# ECC_AGGR10_ECC_AGGR register map
Vendor: Texas Instruments
Peripheral module from a debugger description file (folder J721S2).
Registers are 32-bit, access not given, reset 0x0 unless marked. A register's access mark holds for its fields unless they carry their own. Offsets are as the file gives them; lines under a group give offsets from that group; [hi:lo] are bit positions; {n}, {i} and the like mark numbered series; 'fields as' and 'values as' point back to an identical list; <NAME> marks a mode.

## ECC_AGGR10_ECC_AGGR
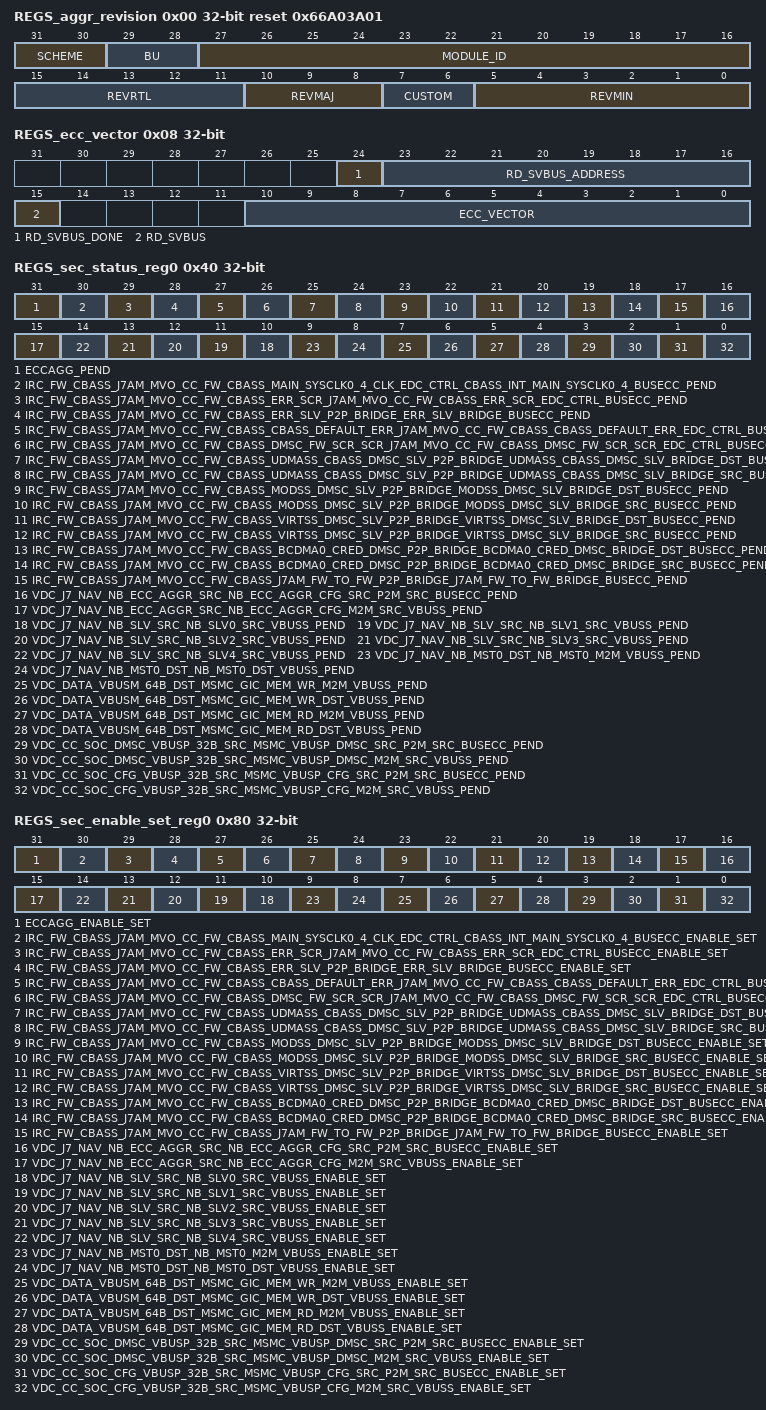
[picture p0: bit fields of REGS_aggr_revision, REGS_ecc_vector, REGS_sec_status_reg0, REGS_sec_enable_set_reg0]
0x00 REGS_aggr_revision ro reset 0x66A03A01 — Revision parameters
  [31:30] SCHEME
  [29:28] BU
  [27:16] MODULE_ID
  [15:11] REVRTL — RTL version
  [10:8] REVMAJ — Major version
  [7:6] CUSTOM — Custom version
  [5:0] REVMIN — Minor version
0x08 REGS_ecc_vector — ECC Vector Register
  [24] RD_SVBUS_DONE — Status to indicate if read on serial VBUS is complete, write of any value will clear this bit. (access R/W1TC)
  [23:16] RD_SVBUS_ADDRESS rw — Read address
  [15] RD_SVBUS — Write 1 to trigger a read on the serial VBUS (access R/W1TS)
  [10:0] ECC_VECTOR rw — Value written to select the corresponding ECC RAM for control or status
0x0C REGS_misc_status ro reset 0x20 — Misc Status
  [10:0] NUM_RAMS — Indicates the number of RAMS serviced by the ECC aggregator
0x10 REGS_reserved_svbus rw — Reference other documents that contain the ECC RAM wrapper and EDC controller serial vbus register sets.
  [31:0] DATA — Serial VBUS register data
0x3C REGS_sec_eoi_reg — EOI Register
  [0] EOI_WR — EOI Register (access R/W1TS)
0x40 REGS_sec_status_reg0 — Interrupt Status Register 0
  [31] ECCAGG_PEND — Interrupt Pending Status for eccagg_pend (access R/W1TS)
  [30] IRC_FW_CBASS_J7AM_MVO_CC_FW_CBASS_MAIN_SYSCLK0_4_CLK_EDC_CTRL_CBASS_INT_MAIN_SYSCLK0_4_BUSECC_PEND — Interrupt Pending Status for Irc_fw_cbass_j7am_mvo_cc_fw_cbass_main_SYSCLK0_4_clk_edc_ctrl_cbass_int_main_SYSCLK0_4_busecc_pend (access R/W1TS)
  [29] IRC_FW_CBASS_J7AM_MVO_CC_FW_CBASS_ERR_SCR_J7AM_MVO_CC_FW_CBASS_ERR_SCR_EDC_CTRL_BUSECC_PEND — Interrupt Pending Status for Irc_fw_cbass_j7am_mvo_cc_fw_cbass_err_scr_j7am_mvo_cc_fw_cbass_err_scr_edc_ctrl_busecc_pend (access R/W1TS)
  [28] IRC_FW_CBASS_J7AM_MVO_CC_FW_CBASS_ERR_SLV_P2P_BRIDGE_ERR_SLV_BRIDGE_BUSECC_PEND — Interrupt Pending Status for Irc_fw_cbass_j7am_mvo_cc_fw_cbass_err_slv_p2p_bridge_err_slv_bridge_busecc_pend (access R/W1TS)
  [27] IRC_FW_CBASS_J7AM_MVO_CC_FW_CBASS_CBASS_DEFAULT_ERR_J7AM_MVO_CC_FW_CBASS_CBASS_DEFAULT_ERR_EDC_CTRL_BUSECC_PEND — Interrupt Pending Status for Irc_fw_cbass_j7am_mvo_cc_fw_cbass_cbass_default_err_j7am_mvo_cc_fw_cbass_cbass_default_err_edc_ctrl_busecc_pend (access R/W1TS)
  [26] IRC_FW_CBASS_J7AM_MVO_CC_FW_CBASS_DMSC_FW_SCR_SCR_J7AM_MVO_CC_FW_CBASS_DMSC_FW_SCR_SCR_EDC_CTRL_BUSECC_PEND — Interrupt Pending Status for Irc_fw_cbass_j7am_mvo_cc_fw_cbass_dmsc_fw_scr_scr_j7am_mvo_cc_fw_cbass_dmsc_fw_scr_scr_edc_ctrl_busecc_pend (access R/W1TS)
  [25] IRC_FW_CBASS_J7AM_MVO_CC_FW_CBASS_UDMASS_CBASS_DMSC_SLV_P2P_BRIDGE_UDMASS_CBASS_DMSC_SLV_BRIDGE_DST_BUSECC_PEND — Interrupt Pending Status for Irc_fw_cbass_j7am_mvo_cc_fw_cbass_udmass_cbass_dmsc_slv_p2p_bridge_udmass_cbass_dmsc_slv_bridge_dst_busecc_pend (access R/W1TS)
  [24] IRC_FW_CBASS_J7AM_MVO_CC_FW_CBASS_UDMASS_CBASS_DMSC_SLV_P2P_BRIDGE_UDMASS_CBASS_DMSC_SLV_BRIDGE_SRC_BUSECC_PEND — Interrupt Pending Status for Irc_fw_cbass_j7am_mvo_cc_fw_cbass_udmass_cbass_dmsc_slv_p2p_bridge_udmass_cbass_dmsc_slv_bridge_src_busecc_pend (access R/W1TS)
  [23] IRC_FW_CBASS_J7AM_MVO_CC_FW_CBASS_MODSS_DMSC_SLV_P2P_BRIDGE_MODSS_DMSC_SLV_BRIDGE_DST_BUSECC_PEND — Interrupt Pending Status for Irc_fw_cbass_j7am_mvo_cc_fw_cbass_modss_dmsc_slv_p2p_bridge_modss_dmsc_slv_bridge_dst_busecc_pend (access R/W1TS)
  [22] IRC_FW_CBASS_J7AM_MVO_CC_FW_CBASS_MODSS_DMSC_SLV_P2P_BRIDGE_MODSS_DMSC_SLV_BRIDGE_SRC_BUSECC_PEND — Interrupt Pending Status for Irc_fw_cbass_j7am_mvo_cc_fw_cbass_modss_dmsc_slv_p2p_bridge_modss_dmsc_slv_bridge_src_busecc_pend (access R/W1TS)
  [21] IRC_FW_CBASS_J7AM_MVO_CC_FW_CBASS_VIRTSS_DMSC_SLV_P2P_BRIDGE_VIRTSS_DMSC_SLV_BRIDGE_DST_BUSECC_PEND — Interrupt Pending Status for Irc_fw_cbass_j7am_mvo_cc_fw_cbass_virtss_dmsc_slv_p2p_bridge_virtss_dmsc_slv_bridge_dst_busecc_pend (access R/W1TS)
  [20] IRC_FW_CBASS_J7AM_MVO_CC_FW_CBASS_VIRTSS_DMSC_SLV_P2P_BRIDGE_VIRTSS_DMSC_SLV_BRIDGE_SRC_BUSECC_PEND — Interrupt Pending Status for Irc_fw_cbass_j7am_mvo_cc_fw_cbass_virtss_dmsc_slv_p2p_bridge_virtss_dmsc_slv_bridge_src_busecc_pend (access R/W1TS)
  [19] IRC_FW_CBASS_J7AM_MVO_CC_FW_CBASS_BCDMA0_CRED_DMSC_P2P_BRIDGE_BCDMA0_CRED_DMSC_BRIDGE_DST_BUSECC_PEND — Interrupt Pending Status for Irc_fw_cbass_j7am_mvo_cc_fw_cbass_bcdma0_cred_dmsc_p2p_bridge_bcdma0_cred_dmsc_bridge_dst_busecc_pend (access R/W1TS)
  [18] IRC_FW_CBASS_J7AM_MVO_CC_FW_CBASS_BCDMA0_CRED_DMSC_P2P_BRIDGE_BCDMA0_CRED_DMSC_BRIDGE_SRC_BUSECC_PEND — Interrupt Pending Status for Irc_fw_cbass_j7am_mvo_cc_fw_cbass_bcdma0_cred_dmsc_p2p_bridge_bcdma0_cred_dmsc_bridge_src_busecc_pend (access R/W1TS)
  [17] IRC_FW_CBASS_J7AM_MVO_CC_FW_CBASS_J7AM_FW_TO_FW_P2P_BRIDGE_J7AM_FW_TO_FW_BRIDGE_BUSECC_PEND — Interrupt Pending Status for Irc_fw_cbass_j7am_mvo_cc_fw_cbass_j7am_fw_to_fw_p2p_bridge_j7am_fw_to_fw_bridge_busecc_pend (access R/W1TS)
  [16] VDC_J7_NAV_NB_ECC_AGGR_SRC_NB_ECC_AGGR_CFG_SRC_P2M_SRC_BUSECC_PEND — Interrupt Pending Status for vdc_j7_nav_nb_ecc_aggr_src_nb_ecc_aggr_cfg_src_p2m_src_busecc_pend (access R/W1TS)
  [15] VDC_J7_NAV_NB_ECC_AGGR_SRC_NB_ECC_AGGR_CFG_M2M_SRC_VBUSS_PEND — Interrupt Pending Status for vdc_j7_nav_nb_ecc_aggr_src_nb_ecc_aggr_cfg_m2m_src_vbuss_pend (access R/W1TS)
  [n+10] VDC_J7_NAV_NB_SLV_SRC_NB_SLV{n}_SRC_VBUSS_PEND (n=0..4) — Interrupt Pending Status for vdc_j7_nav_nb_slv_src_nb_slv{n}_src_vbuss_pend (access R/W1TS)
  [9] VDC_J7_NAV_NB_MST0_DST_NB_MST0_M2M_VBUSS_PEND — Interrupt Pending Status for vdc_j7_nav_nb_mst0_dst_nb_mst0_m2m_vbuss_pend (access R/W1TS)
  [8] VDC_J7_NAV_NB_MST0_DST_NB_MST0_DST_VBUSS_PEND — Interrupt Pending Status for vdc_j7_nav_nb_mst0_dst_nb_mst0_dst_vbuss_pend (access R/W1TS)
  [7] VDC_DATA_VBUSM_64B_DST_MSMC_GIC_MEM_WR_M2M_VBUSS_PEND — Interrupt Pending Status for vdc_data_vbusm_64b_dst_msmc_gic_mem_wr_m2m_vbuss_pend (access R/W1TS)
  [6] VDC_DATA_VBUSM_64B_DST_MSMC_GIC_MEM_WR_DST_VBUSS_PEND — Interrupt Pending Status for vdc_data_vbusm_64b_dst_msmc_gic_mem_wr_dst_vbuss_pend (access R/W1TS)
  [5] VDC_DATA_VBUSM_64B_DST_MSMC_GIC_MEM_RD_M2M_VBUSS_PEND — Interrupt Pending Status for vdc_data_vbusm_64b_dst_msmc_gic_mem_rd_m2m_vbuss_pend (access R/W1TS)
  [4] VDC_DATA_VBUSM_64B_DST_MSMC_GIC_MEM_RD_DST_VBUSS_PEND — Interrupt Pending Status for vdc_data_vbusm_64b_dst_msmc_gic_mem_rd_dst_vbuss_pend (access R/W1TS)
  [3] VDC_CC_SOC_DMSC_VBUSP_32B_SRC_MSMC_VBUSP_DMSC_SRC_P2M_SRC_BUSECC_PEND — Interrupt Pending Status for vdc_cc_soc_dmsc_vbusp_32b_src_msmc_vbusp_dmsc_src_p2m_src_busecc_pend (access R/W1TS)
  [2] VDC_CC_SOC_DMSC_VBUSP_32B_SRC_MSMC_VBUSP_DMSC_M2M_SRC_VBUSS_PEND — Interrupt Pending Status for vdc_cc_soc_dmsc_vbusp_32b_src_msmc_vbusp_dmsc_m2m_src_vbuss_pend (access R/W1TS)
  [1] VDC_CC_SOC_CFG_VBUSP_32B_SRC_MSMC_VBUSP_CFG_SRC_P2M_SRC_BUSECC_PEND — Interrupt Pending Status for vdc_cc_soc_cfg_vbusp_32b_src_msmc_vbusp_cfg_src_p2m_src_busecc_pend (access R/W1TS)
  [0] VDC_CC_SOC_CFG_VBUSP_32B_SRC_MSMC_VBUSP_CFG_M2M_SRC_VBUSS_PEND — Interrupt Pending Status for vdc_cc_soc_cfg_vbusp_32b_src_msmc_vbusp_cfg_m2m_src_vbuss_pend (access R/W1TS)
0x80 REGS_sec_enable_set_reg0 — Interrupt Enable Set Register 0
  [31] ECCAGG_ENABLE_SET — Interrupt Enable Set Register for eccagg_pend (access R/W1TS)
  [30] IRC_FW_CBASS_J7AM_MVO_CC_FW_CBASS_MAIN_SYSCLK0_4_CLK_EDC_CTRL_CBASS_INT_MAIN_SYSCLK0_4_BUSECC_ENABLE_SET — Interrupt Enable Set Register for Irc_fw_cbass_j7am_mvo_cc_fw_cbass_main_SYSCLK0_4_clk_edc_ctrl_cbass_int_main_SYSCLK0_4_busecc_pend (access R/W1TS)
  [29] IRC_FW_CBASS_J7AM_MVO_CC_FW_CBASS_ERR_SCR_J7AM_MVO_CC_FW_CBASS_ERR_SCR_EDC_CTRL_BUSECC_ENABLE_SET — Interrupt Enable Set Register for Irc_fw_cbass_j7am_mvo_cc_fw_cbass_err_scr_j7am_mvo_cc_fw_cbass_err_scr_edc_ctrl_busecc_pend (access R/W1TS)
  [28] IRC_FW_CBASS_J7AM_MVO_CC_FW_CBASS_ERR_SLV_P2P_BRIDGE_ERR_SLV_BRIDGE_BUSECC_ENABLE_SET — Interrupt Enable Set Register for Irc_fw_cbass_j7am_mvo_cc_fw_cbass_err_slv_p2p_bridge_err_slv_bridge_busecc_pend (access R/W1TS)
  [27] IRC_FW_CBASS_J7AM_MVO_CC_FW_CBASS_CBASS_DEFAULT_ERR_J7AM_MVO_CC_FW_CBASS_CBASS_DEFAULT_ERR_EDC_CTRL_BUSECC_ENABLE_SET — Interrupt Enable Set Register for Irc_fw_cbass_j7am_mvo_cc_fw_cbass_cbass_default_err_j7am_mvo_cc_fw_cbass_cbass_default_err_edc_ctrl_busecc_pend (access R/W1TS)
  [26] IRC_FW_CBASS_J7AM_MVO_CC_FW_CBASS_DMSC_FW_SCR_SCR_J7AM_MVO_CC_FW_CBASS_DMSC_FW_SCR_SCR_EDC_CTRL_BUSECC_ENABLE_SET — Interrupt Enable Set Register for Irc_fw_cbass_j7am_mvo_cc_fw_cbass_dmsc_fw_scr_scr_j7am_mvo_cc_fw_cbass_dmsc_fw_scr_scr_edc_ctrl_busecc_pend (access R/W1TS)
  [25] IRC_FW_CBASS_J7AM_MVO_CC_FW_CBASS_UDMASS_CBASS_DMSC_SLV_P2P_BRIDGE_UDMASS_CBASS_DMSC_SLV_BRIDGE_DST_BUSECC_ENABLE_SET — Interrupt Enable Set Register for Irc_fw_cbass_j7am_mvo_cc_fw_cbass_udmass_cbass_dmsc_slv_p2p_bridge_udmass_cbass_dmsc_slv_bridge_dst_busecc_pend (access R/W1TS)
  [24] IRC_FW_CBASS_J7AM_MVO_CC_FW_CBASS_UDMASS_CBASS_DMSC_SLV_P2P_BRIDGE_UDMASS_CBASS_DMSC_SLV_BRIDGE_SRC_BUSECC_ENABLE_SET — Interrupt Enable Set Register for Irc_fw_cbass_j7am_mvo_cc_fw_cbass_udmass_cbass_dmsc_slv_p2p_bridge_udmass_cbass_dmsc_slv_bridge_src_busecc_pend (access R/W1TS)
  [23] IRC_FW_CBASS_J7AM_MVO_CC_FW_CBASS_MODSS_DMSC_SLV_P2P_BRIDGE_MODSS_DMSC_SLV_BRIDGE_DST_BUSECC_ENABLE_SET — Interrupt Enable Set Register for Irc_fw_cbass_j7am_mvo_cc_fw_cbass_modss_dmsc_slv_p2p_bridge_modss_dmsc_slv_bridge_dst_busecc_pend (access R/W1TS)
  [22] IRC_FW_CBASS_J7AM_MVO_CC_FW_CBASS_MODSS_DMSC_SLV_P2P_BRIDGE_MODSS_DMSC_SLV_BRIDGE_SRC_BUSECC_ENABLE_SET — Interrupt Enable Set Register for Irc_fw_cbass_j7am_mvo_cc_fw_cbass_modss_dmsc_slv_p2p_bridge_modss_dmsc_slv_bridge_src_busecc_pend (access R/W1TS)
  [21] IRC_FW_CBASS_J7AM_MVO_CC_FW_CBASS_VIRTSS_DMSC_SLV_P2P_BRIDGE_VIRTSS_DMSC_SLV_BRIDGE_DST_BUSECC_ENABLE_SET — Interrupt Enable Set Register for Irc_fw_cbass_j7am_mvo_cc_fw_cbass_virtss_dmsc_slv_p2p_bridge_virtss_dmsc_slv_bridge_dst_busecc_pend (access R/W1TS)
  [20] IRC_FW_CBASS_J7AM_MVO_CC_FW_CBASS_VIRTSS_DMSC_SLV_P2P_BRIDGE_VIRTSS_DMSC_SLV_BRIDGE_SRC_BUSECC_ENABLE_SET — Interrupt Enable Set Register for Irc_fw_cbass_j7am_mvo_cc_fw_cbass_virtss_dmsc_slv_p2p_bridge_virtss_dmsc_slv_bridge_src_busecc_pend (access R/W1TS)
  [19] IRC_FW_CBASS_J7AM_MVO_CC_FW_CBASS_BCDMA0_CRED_DMSC_P2P_BRIDGE_BCDMA0_CRED_DMSC_BRIDGE_DST_BUSECC_ENABLE_SET — Interrupt Enable Set Register for Irc_fw_cbass_j7am_mvo_cc_fw_cbass_bcdma0_cred_dmsc_p2p_bridge_bcdma0_cred_dmsc_bridge_dst_busecc_pend (access R/W1TS)
  [18] IRC_FW_CBASS_J7AM_MVO_CC_FW_CBASS_BCDMA0_CRED_DMSC_P2P_BRIDGE_BCDMA0_CRED_DMSC_BRIDGE_SRC_BUSECC_ENABLE_SET — Interrupt Enable Set Register for Irc_fw_cbass_j7am_mvo_cc_fw_cbass_bcdma0_cred_dmsc_p2p_bridge_bcdma0_cred_dmsc_bridge_src_busecc_pend (access R/W1TS)
  [17] IRC_FW_CBASS_J7AM_MVO_CC_FW_CBASS_J7AM_FW_TO_FW_P2P_BRIDGE_J7AM_FW_TO_FW_BRIDGE_BUSECC_ENABLE_SET — Interrupt Enable Set Register for Irc_fw_cbass_j7am_mvo_cc_fw_cbass_j7am_fw_to_fw_p2p_bridge_j7am_fw_to_fw_bridge_busecc_pend (access R/W1TS)
  [16] VDC_J7_NAV_NB_ECC_AGGR_SRC_NB_ECC_AGGR_CFG_SRC_P2M_SRC_BUSECC_ENABLE_SET — Interrupt Enable Set Register for vdc_j7_nav_nb_ecc_aggr_src_nb_ecc_aggr_cfg_src_p2m_src_busecc_pend (access R/W1TS)
  [15] VDC_J7_NAV_NB_ECC_AGGR_SRC_NB_ECC_AGGR_CFG_M2M_SRC_VBUSS_ENABLE_SET — Interrupt Enable Set Register for vdc_j7_nav_nb_ecc_aggr_src_nb_ecc_aggr_cfg_m2m_src_vbuss_pend (access R/W1TS)
  [n+10] VDC_J7_NAV_NB_SLV_SRC_NB_SLV{n}_SRC_VBUSS_ENABLE_SET (n=0..4) — Interrupt Enable Set Register for vdc_j7_nav_nb_slv_src_nb_slv{n}_src_vbuss_pend (access R/W1TS)
  [9] VDC_J7_NAV_NB_MST0_DST_NB_MST0_M2M_VBUSS_ENABLE_SET — Interrupt Enable Set Register for vdc_j7_nav_nb_mst0_dst_nb_mst0_m2m_vbuss_pend (access R/W1TS)
  [8] VDC_J7_NAV_NB_MST0_DST_NB_MST0_DST_VBUSS_ENABLE_SET — Interrupt Enable Set Register for vdc_j7_nav_nb_mst0_dst_nb_mst0_dst_vbuss_pend (access R/W1TS)
  [7] VDC_DATA_VBUSM_64B_DST_MSMC_GIC_MEM_WR_M2M_VBUSS_ENABLE_SET — Interrupt Enable Set Register for vdc_data_vbusm_64b_dst_msmc_gic_mem_wr_m2m_vbuss_pend (access R/W1TS)
  [6] VDC_DATA_VBUSM_64B_DST_MSMC_GIC_MEM_WR_DST_VBUSS_ENABLE_SET — Interrupt Enable Set Register for vdc_data_vbusm_64b_dst_msmc_gic_mem_wr_dst_vbuss_pend (access R/W1TS)
  [5] VDC_DATA_VBUSM_64B_DST_MSMC_GIC_MEM_RD_M2M_VBUSS_ENABLE_SET — Interrupt Enable Set Register for vdc_data_vbusm_64b_dst_msmc_gic_mem_rd_m2m_vbuss_pend (access R/W1TS)
  [4] VDC_DATA_VBUSM_64B_DST_MSMC_GIC_MEM_RD_DST_VBUSS_ENABLE_SET — Interrupt Enable Set Register for vdc_data_vbusm_64b_dst_msmc_gic_mem_rd_dst_vbuss_pend (access R/W1TS)
  [3] VDC_CC_SOC_DMSC_VBUSP_32B_SRC_MSMC_VBUSP_DMSC_SRC_P2M_SRC_BUSECC_ENABLE_SET — Interrupt Enable Set Register for vdc_cc_soc_dmsc_vbusp_32b_src_msmc_vbusp_dmsc_src_p2m_src_busecc_pend (access R/W1TS)
  [2] VDC_CC_SOC_DMSC_VBUSP_32B_SRC_MSMC_VBUSP_DMSC_M2M_SRC_VBUSS_ENABLE_SET — Interrupt Enable Set Register for vdc_cc_soc_dmsc_vbusp_32b_src_msmc_vbusp_dmsc_m2m_src_vbuss_pend (access R/W1TS)
  [1] VDC_CC_SOC_CFG_VBUSP_32B_SRC_MSMC_VBUSP_CFG_SRC_P2M_SRC_BUSECC_ENABLE_SET — Interrupt Enable Set Register for vdc_cc_soc_cfg_vbusp_32b_src_msmc_vbusp_cfg_src_p2m_src_busecc_pend (access R/W1TS)
  [0] VDC_CC_SOC_CFG_VBUSP_32B_SRC_MSMC_VBUSP_CFG_M2M_SRC_VBUSS_ENABLE_SET — Interrupt Enable Set Register for vdc_cc_soc_cfg_vbusp_32b_src_msmc_vbusp_cfg_m2m_src_vbuss_pend (access R/W1TS)
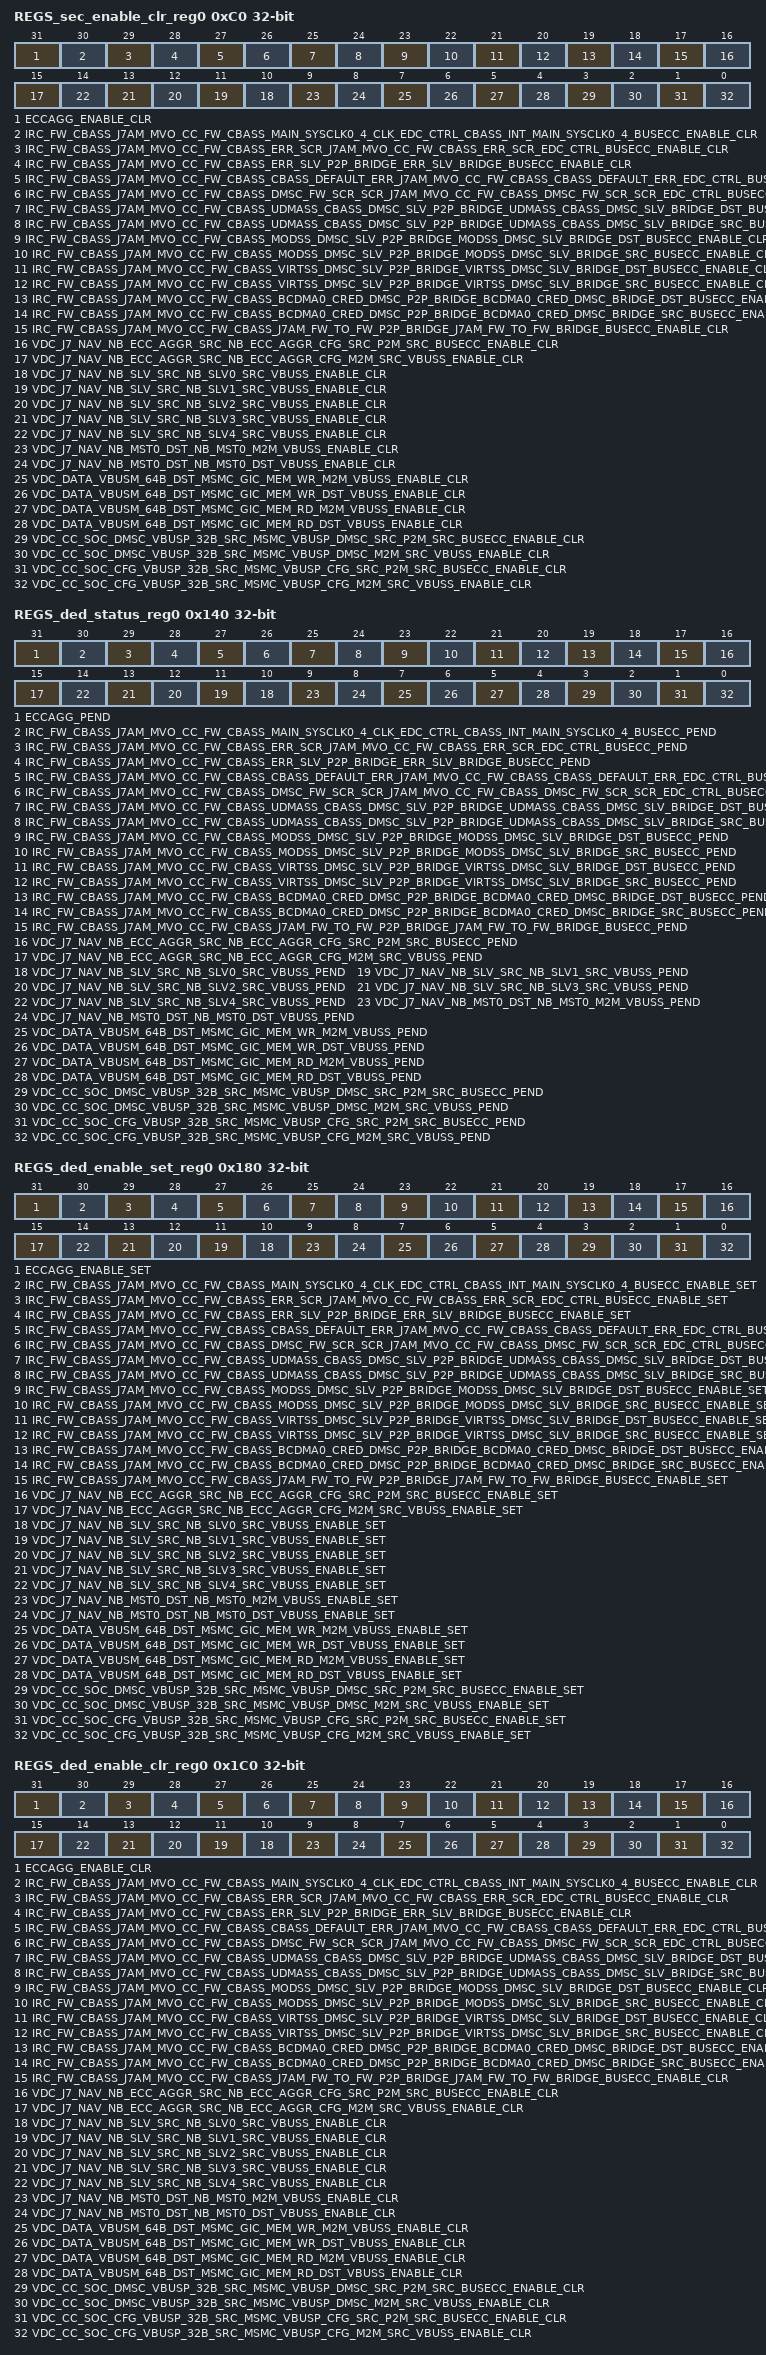
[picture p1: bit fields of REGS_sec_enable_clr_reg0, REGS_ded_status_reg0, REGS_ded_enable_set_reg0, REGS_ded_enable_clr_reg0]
0xC0 REGS_sec_enable_clr_reg0 — Interrupt Enable Clear Register 0
  [31] ECCAGG_ENABLE_CLR — Interrupt Enable Clear Register for eccagg_pend (access R/W1TC)
  [30] IRC_FW_CBASS_J7AM_MVO_CC_FW_CBASS_MAIN_SYSCLK0_4_CLK_EDC_CTRL_CBASS_INT_MAIN_SYSCLK0_4_BUSECC_ENABLE_CLR — Interrupt Enable Clear Register for Irc_fw_cbass_j7am_mvo_cc_fw_cbass_main_SYSCLK0_4_clk_edc_ctrl_cbass_int_main_SYSCLK0_4_busecc_pend (access R/W1TC)
  [29] IRC_FW_CBASS_J7AM_MVO_CC_FW_CBASS_ERR_SCR_J7AM_MVO_CC_FW_CBASS_ERR_SCR_EDC_CTRL_BUSECC_ENABLE_CLR — Interrupt Enable Clear Register for Irc_fw_cbass_j7am_mvo_cc_fw_cbass_err_scr_j7am_mvo_cc_fw_cbass_err_scr_edc_ctrl_busecc_pend (access R/W1TC)
  [28] IRC_FW_CBASS_J7AM_MVO_CC_FW_CBASS_ERR_SLV_P2P_BRIDGE_ERR_SLV_BRIDGE_BUSECC_ENABLE_CLR — Interrupt Enable Clear Register for Irc_fw_cbass_j7am_mvo_cc_fw_cbass_err_slv_p2p_bridge_err_slv_bridge_busecc_pend (access R/W1TC)
  [27] IRC_FW_CBASS_J7AM_MVO_CC_FW_CBASS_CBASS_DEFAULT_ERR_J7AM_MVO_CC_FW_CBASS_CBASS_DEFAULT_ERR_EDC_CTRL_BUSECC_ENABLE_CLR — Interrupt Enable Clear Register for Irc_fw_cbass_j7am_mvo_cc_fw_cbass_cbass_default_err_j7am_mvo_cc_fw_cbass_cbass_default_err_edc_ctrl_busecc_pend (access R/W1TC)
  [26] IRC_FW_CBASS_J7AM_MVO_CC_FW_CBASS_DMSC_FW_SCR_SCR_J7AM_MVO_CC_FW_CBASS_DMSC_FW_SCR_SCR_EDC_CTRL_BUSECC_ENABLE_CLR — Interrupt Enable Clear Register for Irc_fw_cbass_j7am_mvo_cc_fw_cbass_dmsc_fw_scr_scr_j7am_mvo_cc_fw_cbass_dmsc_fw_scr_scr_edc_ctrl_busecc_pend (access R/W1TC)
  [25] IRC_FW_CBASS_J7AM_MVO_CC_FW_CBASS_UDMASS_CBASS_DMSC_SLV_P2P_BRIDGE_UDMASS_CBASS_DMSC_SLV_BRIDGE_DST_BUSECC_ENABLE_CLR — Interrupt Enable Clear Register for Irc_fw_cbass_j7am_mvo_cc_fw_cbass_udmass_cbass_dmsc_slv_p2p_bridge_udmass_cbass_dmsc_slv_bridge_dst_busecc_pend (access R/W1TC)
  [24] IRC_FW_CBASS_J7AM_MVO_CC_FW_CBASS_UDMASS_CBASS_DMSC_SLV_P2P_BRIDGE_UDMASS_CBASS_DMSC_SLV_BRIDGE_SRC_BUSECC_ENABLE_CLR — Interrupt Enable Clear Register for Irc_fw_cbass_j7am_mvo_cc_fw_cbass_udmass_cbass_dmsc_slv_p2p_bridge_udmass_cbass_dmsc_slv_bridge_src_busecc_pend (access R/W1TC)
  [23] IRC_FW_CBASS_J7AM_MVO_CC_FW_CBASS_MODSS_DMSC_SLV_P2P_BRIDGE_MODSS_DMSC_SLV_BRIDGE_DST_BUSECC_ENABLE_CLR — Interrupt Enable Clear Register for Irc_fw_cbass_j7am_mvo_cc_fw_cbass_modss_dmsc_slv_p2p_bridge_modss_dmsc_slv_bridge_dst_busecc_pend (access R/W1TC)
  [22] IRC_FW_CBASS_J7AM_MVO_CC_FW_CBASS_MODSS_DMSC_SLV_P2P_BRIDGE_MODSS_DMSC_SLV_BRIDGE_SRC_BUSECC_ENABLE_CLR — Interrupt Enable Clear Register for Irc_fw_cbass_j7am_mvo_cc_fw_cbass_modss_dmsc_slv_p2p_bridge_modss_dmsc_slv_bridge_src_busecc_pend (access R/W1TC)
  [21] IRC_FW_CBASS_J7AM_MVO_CC_FW_CBASS_VIRTSS_DMSC_SLV_P2P_BRIDGE_VIRTSS_DMSC_SLV_BRIDGE_DST_BUSECC_ENABLE_CLR — Interrupt Enable Clear Register for Irc_fw_cbass_j7am_mvo_cc_fw_cbass_virtss_dmsc_slv_p2p_bridge_virtss_dmsc_slv_bridge_dst_busecc_pend (access R/W1TC)
  [20] IRC_FW_CBASS_J7AM_MVO_CC_FW_CBASS_VIRTSS_DMSC_SLV_P2P_BRIDGE_VIRTSS_DMSC_SLV_BRIDGE_SRC_BUSECC_ENABLE_CLR — Interrupt Enable Clear Register for Irc_fw_cbass_j7am_mvo_cc_fw_cbass_virtss_dmsc_slv_p2p_bridge_virtss_dmsc_slv_bridge_src_busecc_pend (access R/W1TC)
  [19] IRC_FW_CBASS_J7AM_MVO_CC_FW_CBASS_BCDMA0_CRED_DMSC_P2P_BRIDGE_BCDMA0_CRED_DMSC_BRIDGE_DST_BUSECC_ENABLE_CLR — Interrupt Enable Clear Register for Irc_fw_cbass_j7am_mvo_cc_fw_cbass_bcdma0_cred_dmsc_p2p_bridge_bcdma0_cred_dmsc_bridge_dst_busecc_pend (access R/W1TC)
  [18] IRC_FW_CBASS_J7AM_MVO_CC_FW_CBASS_BCDMA0_CRED_DMSC_P2P_BRIDGE_BCDMA0_CRED_DMSC_BRIDGE_SRC_BUSECC_ENABLE_CLR — Interrupt Enable Clear Register for Irc_fw_cbass_j7am_mvo_cc_fw_cbass_bcdma0_cred_dmsc_p2p_bridge_bcdma0_cred_dmsc_bridge_src_busecc_pend (access R/W1TC)
  [17] IRC_FW_CBASS_J7AM_MVO_CC_FW_CBASS_J7AM_FW_TO_FW_P2P_BRIDGE_J7AM_FW_TO_FW_BRIDGE_BUSECC_ENABLE_CLR — Interrupt Enable Clear Register for Irc_fw_cbass_j7am_mvo_cc_fw_cbass_j7am_fw_to_fw_p2p_bridge_j7am_fw_to_fw_bridge_busecc_pend (access R/W1TC)
  [16] VDC_J7_NAV_NB_ECC_AGGR_SRC_NB_ECC_AGGR_CFG_SRC_P2M_SRC_BUSECC_ENABLE_CLR — Interrupt Enable Clear Register for vdc_j7_nav_nb_ecc_aggr_src_nb_ecc_aggr_cfg_src_p2m_src_busecc_pend (access R/W1TC)
  [15] VDC_J7_NAV_NB_ECC_AGGR_SRC_NB_ECC_AGGR_CFG_M2M_SRC_VBUSS_ENABLE_CLR — Interrupt Enable Clear Register for vdc_j7_nav_nb_ecc_aggr_src_nb_ecc_aggr_cfg_m2m_src_vbuss_pend (access R/W1TC)
  [n+10] VDC_J7_NAV_NB_SLV_SRC_NB_SLV{n}_SRC_VBUSS_ENABLE_CLR (n=0..4) — Interrupt Enable Clear Register for vdc_j7_nav_nb_slv_src_nb_slv{n}_src_vbuss_pend (access R/W1TC)
  [9] VDC_J7_NAV_NB_MST0_DST_NB_MST0_M2M_VBUSS_ENABLE_CLR — Interrupt Enable Clear Register for vdc_j7_nav_nb_mst0_dst_nb_mst0_m2m_vbuss_pend (access R/W1TC)
  [8] VDC_J7_NAV_NB_MST0_DST_NB_MST0_DST_VBUSS_ENABLE_CLR — Interrupt Enable Clear Register for vdc_j7_nav_nb_mst0_dst_nb_mst0_dst_vbuss_pend (access R/W1TC)
  [7] VDC_DATA_VBUSM_64B_DST_MSMC_GIC_MEM_WR_M2M_VBUSS_ENABLE_CLR — Interrupt Enable Clear Register for vdc_data_vbusm_64b_dst_msmc_gic_mem_wr_m2m_vbuss_pend (access R/W1TC)
  [6] VDC_DATA_VBUSM_64B_DST_MSMC_GIC_MEM_WR_DST_VBUSS_ENABLE_CLR — Interrupt Enable Clear Register for vdc_data_vbusm_64b_dst_msmc_gic_mem_wr_dst_vbuss_pend (access R/W1TC)
  [5] VDC_DATA_VBUSM_64B_DST_MSMC_GIC_MEM_RD_M2M_VBUSS_ENABLE_CLR — Interrupt Enable Clear Register for vdc_data_vbusm_64b_dst_msmc_gic_mem_rd_m2m_vbuss_pend (access R/W1TC)
  [4] VDC_DATA_VBUSM_64B_DST_MSMC_GIC_MEM_RD_DST_VBUSS_ENABLE_CLR — Interrupt Enable Clear Register for vdc_data_vbusm_64b_dst_msmc_gic_mem_rd_dst_vbuss_pend (access R/W1TC)
  [3] VDC_CC_SOC_DMSC_VBUSP_32B_SRC_MSMC_VBUSP_DMSC_SRC_P2M_SRC_BUSECC_ENABLE_CLR — Interrupt Enable Clear Register for vdc_cc_soc_dmsc_vbusp_32b_src_msmc_vbusp_dmsc_src_p2m_src_busecc_pend (access R/W1TC)
  [2] VDC_CC_SOC_DMSC_VBUSP_32B_SRC_MSMC_VBUSP_DMSC_M2M_SRC_VBUSS_ENABLE_CLR — Interrupt Enable Clear Register for vdc_cc_soc_dmsc_vbusp_32b_src_msmc_vbusp_dmsc_m2m_src_vbuss_pend (access R/W1TC)
  [1] VDC_CC_SOC_CFG_VBUSP_32B_SRC_MSMC_VBUSP_CFG_SRC_P2M_SRC_BUSECC_ENABLE_CLR — Interrupt Enable Clear Register for vdc_cc_soc_cfg_vbusp_32b_src_msmc_vbusp_cfg_src_p2m_src_busecc_pend (access R/W1TC)
  [0] VDC_CC_SOC_CFG_VBUSP_32B_SRC_MSMC_VBUSP_CFG_M2M_SRC_VBUSS_ENABLE_CLR — Interrupt Enable Clear Register for vdc_cc_soc_cfg_vbusp_32b_src_msmc_vbusp_cfg_m2m_src_vbuss_pend (access R/W1TC)
0x13C REGS_ded_eoi_reg — EOI Register
  [0] EOI_WR — EOI Register (access R/W1TS)
0x140 REGS_ded_status_reg0 — Interrupt Status Register 0
  fields as REGS_sec_status_reg0
0x180 REGS_ded_enable_set_reg0 — Interrupt Enable Set Register 0
  fields as REGS_sec_enable_set_reg0
0x1C0 REGS_ded_enable_clr_reg0 — Interrupt Enable Clear Register 0
  fields as REGS_sec_enable_clr_reg0
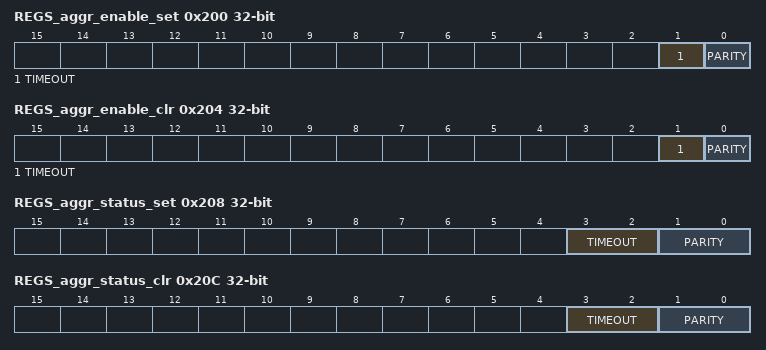
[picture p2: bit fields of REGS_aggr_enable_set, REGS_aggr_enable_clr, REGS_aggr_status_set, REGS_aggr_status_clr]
0x200 REGS_aggr_enable_set — AGGR interrupt enable set Register
  [1] TIMEOUT — interrupt enable set for svbus timeout errors (access R/W1TS)
  [0] PARITY — interrupt enable set for parity errors (access R/W1TS)
0x204 REGS_aggr_enable_clr — AGGR interrupt enable clear Register
  [1] TIMEOUT — interrupt enable clear for svbus timeout errors (access R/W1TC)
  [0] PARITY — interrupt enable clear for parity errors (access R/W1TC)
0x208 REGS_aggr_status_set — AGGR interrupt status set Register
  [3:2] TIMEOUT — interrupt status set for svbus timeout errors (access R/WI)
  [1:0] PARITY — interrupt status set for parity errors (access R/WI)
0x20C REGS_aggr_status_clr — AGGR interrupt status clear Register
  [3:2] TIMEOUT — interrupt status clear for svbus timeout errors (access R/WD)
  [1:0] PARITY — interrupt status clear for parity errors (access R/WD)
